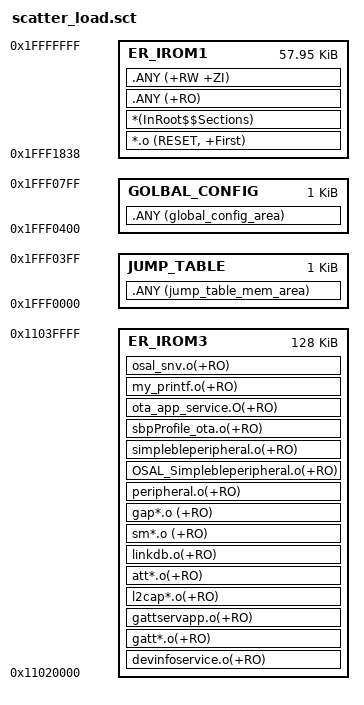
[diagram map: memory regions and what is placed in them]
; *************************************************************
; *** Scatter-Loading Description File generated by uVision ***
; *************************************************************

LR_IROM1 0x1fff1838 0x0E7C8 {  ; load region size_region
 ER_IROM1 0x1fff1838 0x0E7C8  {  ; load address = execution address
  *.o (RESET, +First)
  *(InRoot$$Sections)
  .ANY (+RO)  
  .ANY (+RW +ZI)
 }
}
LR_IROM4  0x1fff0000 0x00800 {
  JUMP_TABLE 0x1fff0000 0x00400  {
   .ANY (jump_table_mem_area) 
	
  }
  GOLBAL_CONFIG 0x1fff0400 0x00400  {
   .ANY (global_config_area) 
	
  }  
 } 
LR_IROM3  0x11020000 0x020000 {
  ER_IROM3 0x11020000 0x020000  {  ; load address = execution address
   ;libethermind_mesh_models.lib (+RO) 
   ;libethermind_utils.lib (+RO) 
   ;libethermind_mesh_core.lib (+RO) 
   ;appl_*.o (+RO)
   ;;;;;
   devinfoservice.o(+RO)
   gatt*.o(+RO)
   gattservapp.o(+RO)
   l2cap*.o(+RO)
   att*.o(+RO)
   linkdb.o(+RO)
   sm*.o (+RO)
   gap*.o (+RO)
   peripheral.o(+RO)
   OSAL_Simplebleperipheral.o(+RO)
   simplebleperipheral.o(+RO)
   sbpProfile_ota.o(+RO)
   ;led_light.o(+RO)
   ota_app_service.O(+RO)
   ;key.o(+RO)
   ;cliface.o(+RO)
   ;fs.o(+RO)
   ;log.o(+RO)
   my_printf.o(+RO)
   osal_snv.o(+RO)
  
  }
 }  



